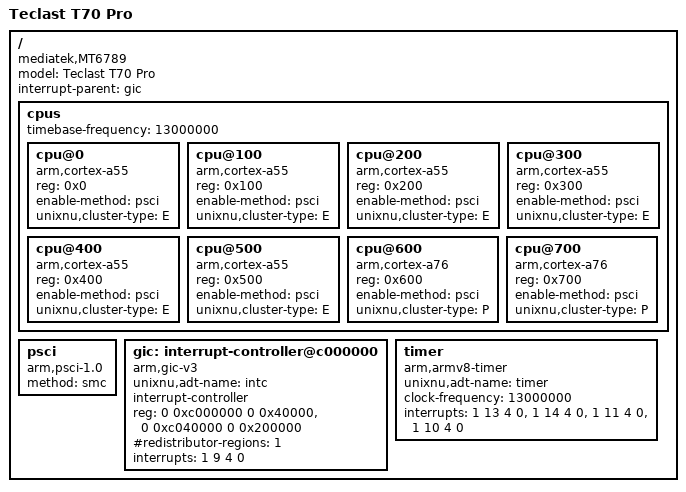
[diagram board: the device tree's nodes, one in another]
/dts-v1/;
/* Generated by analyze-stock.py from effective.dtb SHA-256 a3dd45e28ee284f1995374091eca9634f68c88dfddc5ecd27a37cdcc877dd391.
 * Board model is a target label; CPU timebase comes from /timer/clock-frequency.
 * Hardware-only: runtime RAM/reservations and GOP must be supplied separately. */
/ {
    model = "Teclast T70 Pro"; compatible = "mediatek,MT6789";
    #address-cells = <2>; #size-cells = <2>; interrupt-parent = <&gic>;
    cpus {
        #address-cells = <1>; #size-cells = <0>; timebase-frequency = <13000000>;
        cpu@0 { device_type = "cpu"; compatible = "arm,cortex-a55"; reg = <0x0>; enable-method = "psci"; unixnu,cluster-type = "E"; };
        cpu@100 { device_type = "cpu"; compatible = "arm,cortex-a55"; reg = <0x100>; enable-method = "psci"; unixnu,cluster-type = "E"; };
        cpu@200 { device_type = "cpu"; compatible = "arm,cortex-a55"; reg = <0x200>; enable-method = "psci"; unixnu,cluster-type = "E"; };
        cpu@300 { device_type = "cpu"; compatible = "arm,cortex-a55"; reg = <0x300>; enable-method = "psci"; unixnu,cluster-type = "E"; };
        cpu@400 { device_type = "cpu"; compatible = "arm,cortex-a55"; reg = <0x400>; enable-method = "psci"; unixnu,cluster-type = "E"; };
        cpu@500 { device_type = "cpu"; compatible = "arm,cortex-a55"; reg = <0x500>; enable-method = "psci"; unixnu,cluster-type = "E"; };
        cpu@600 { device_type = "cpu"; compatible = "arm,cortex-a76"; reg = <0x600>; enable-method = "psci"; unixnu,cluster-type = "P"; };
        cpu@700 { device_type = "cpu"; compatible = "arm,cortex-a76"; reg = <0x700>; enable-method = "psci"; unixnu,cluster-type = "P"; };
    };
    psci { compatible = "arm,psci-1.0"; method = "smc"; };
    gic: interrupt-controller@c000000 {
        unixnu,adt-name = "intc"; compatible = "arm,gic-v3";
        interrupt-controller; #interrupt-cells = <4>; #address-cells = <2>; #size-cells = <2>; ranges;
        reg = <0 0xc000000 0 0x40000>, <0 0xc040000 0 0x200000>;
        #redistributor-regions = <1>; interrupts = <1 9 4 0>;
    };
    timer { unixnu,adt-name = "timer"; compatible = "arm,armv8-timer";
        clock-frequency = <13000000>;
        interrupts = <1 13 4 0>, <1 14 4 0>, <1 11 4 0>, <1 10 4 0>;
    };
};
